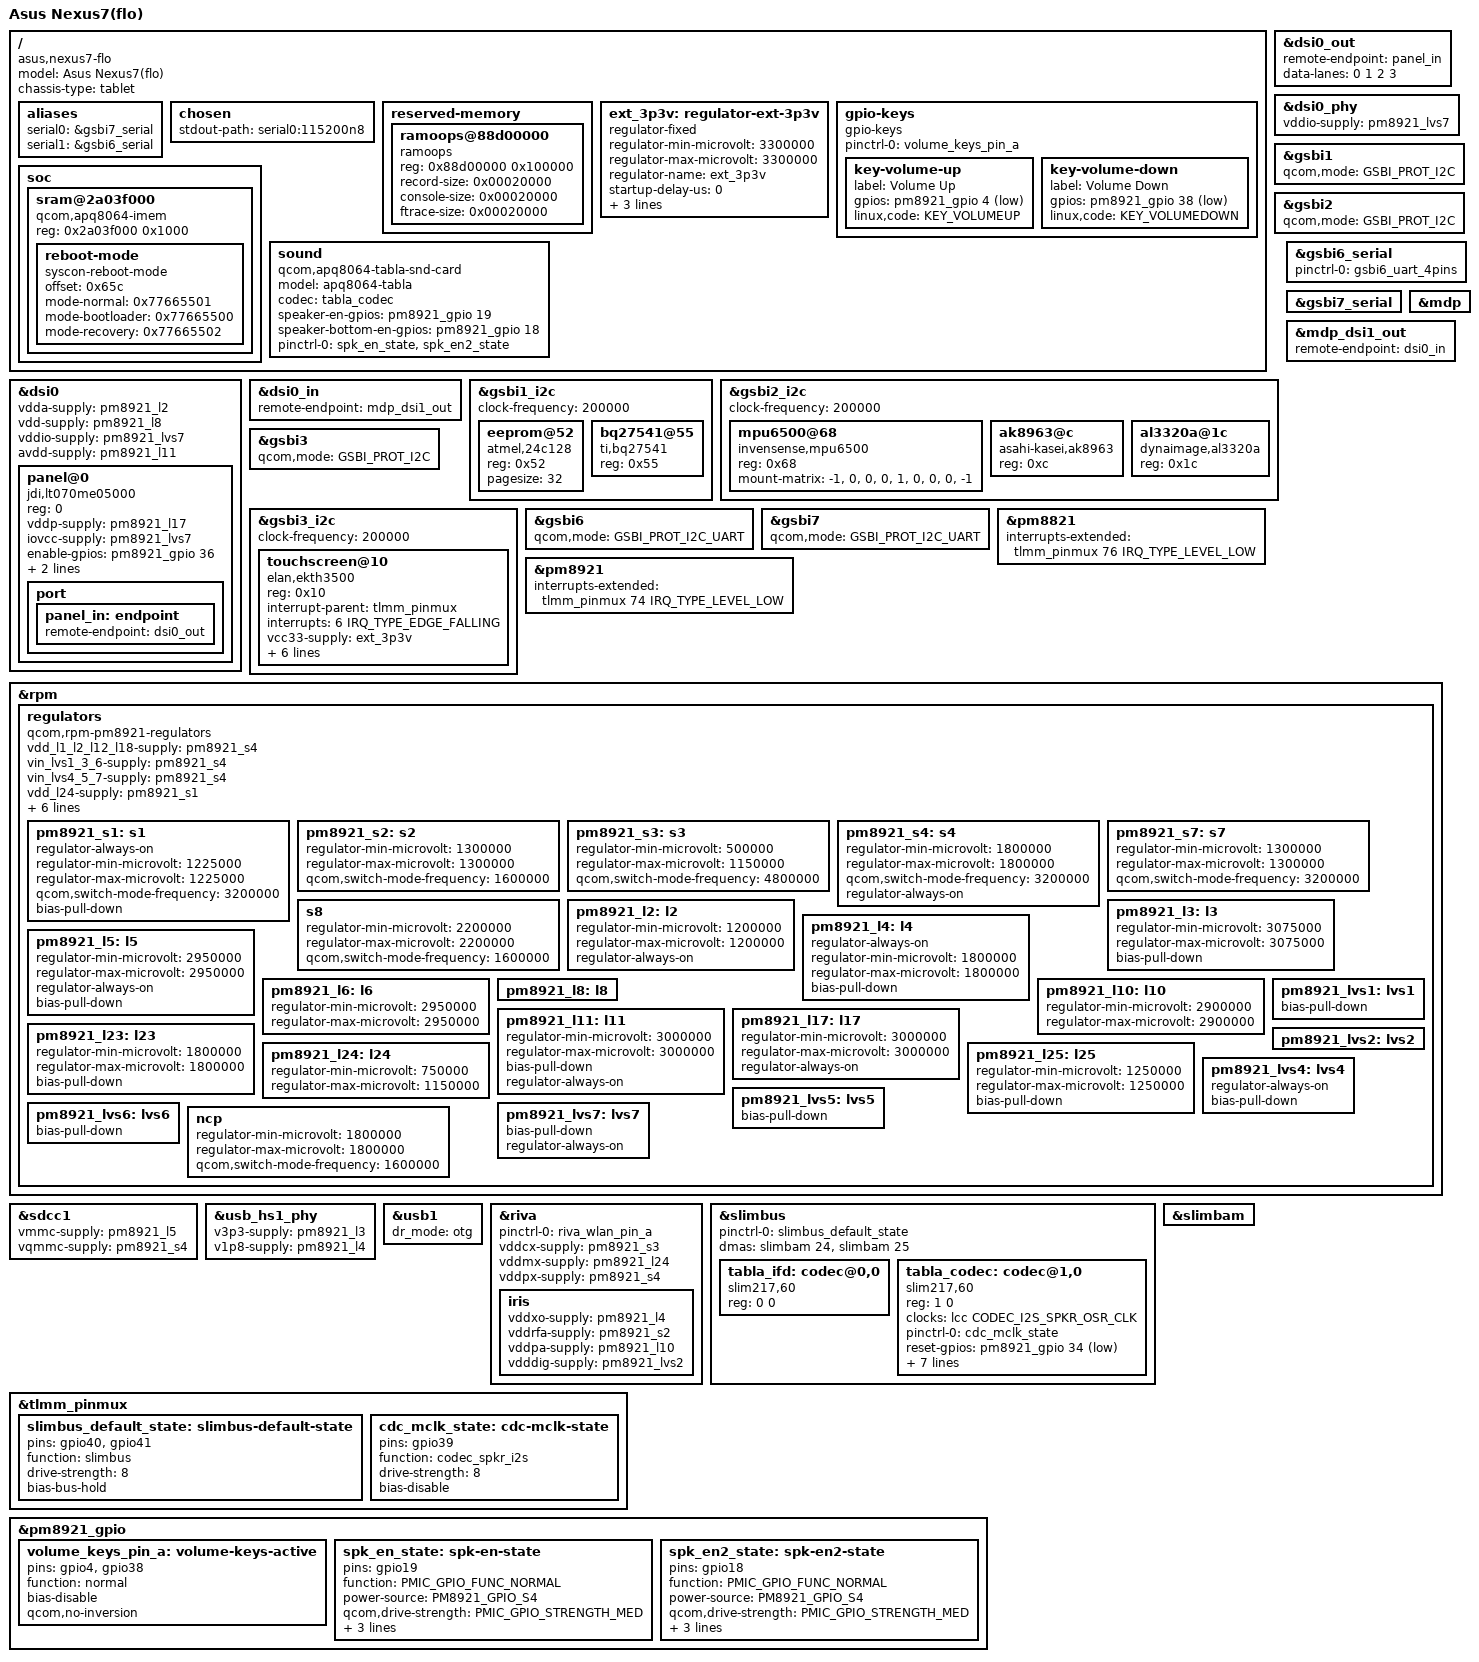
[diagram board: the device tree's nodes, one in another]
// SPDX-License-Identifier: GPL-2.0
#include <dt-bindings/gpio/gpio.h>
#include <dt-bindings/input/input.h>
#include <dt-bindings/pinctrl/qcom,pmic-gpio.h>
#include <dt-bindings/clock/qcom,lcc-msm8960.h>

#include "qcom-apq8064-v2.0.dtsi"
#include "pm8821.dtsi"
#include "pm8921.dtsi"

/ {
	model = "Asus Nexus7(flo)";
	compatible = "asus,nexus7-flo", "qcom,apq8064";
	chassis-type = "tablet";

	aliases {
		serial0 = &gsbi7_serial;
		serial1 = &gsbi6_serial;
	};

	chosen {
		stdout-path = "serial0:115200n8";
	};

	reserved-memory {
		#address-cells = <1>;
		#size-cells = <1>;
		ranges;

		ramoops@88d00000 {
			compatible = "ramoops";
			reg = <0x88d00000 0x100000>;
			record-size = <0x00020000>;
			console-size = <0x00020000>;
			ftrace-size = <0x00020000>;
		};
	};

	ext_3p3v: regulator-ext-3p3v {
		compatible = "regulator-fixed";
		regulator-min-microvolt = <3300000>;
		regulator-max-microvolt = <3300000>;
		regulator-name = "ext_3p3v";
		startup-delay-us = <0>;
		gpio = <&tlmm_pinmux 77 GPIO_ACTIVE_HIGH>;
		enable-active-high;
		regulator-boot-on;
	};

	gpio-keys {
		compatible = "gpio-keys";
		pinctrl-names = "default";
		pinctrl-0 = <&volume_keys_pin_a>;

		key-volume-up {
			label = "Volume Up";
			gpios = <&pm8921_gpio 4 GPIO_ACTIVE_LOW>;
			linux,code = <KEY_VOLUMEUP>;
		};
		key-volume-down {
			label = "Volume Down";
			gpios = <&pm8921_gpio 38 GPIO_ACTIVE_LOW>;
			linux,code = <KEY_VOLUMEDOWN>;
		};
	};

	soc {
		sram@2a03f000 {
			compatible = "qcom,apq8064-imem", "syscon", "simple-mfd";
			reg = <0x2a03f000 0x1000>;

			reboot-mode {
				compatible = "syscon-reboot-mode";
				offset = <0x65c>;

				mode-normal = <0x77665501>;
				mode-bootloader = <0x77665500>;
				mode-recovery = <0x77665502>;
			};
		};
	};

	sound {
		compatible = "qcom,apq8064-tabla-snd-card";
		model = "apq8064-tabla";
		codec = <&tabla_codec>;
		speaker-en-gpios = <&pm8921_gpio 19 GPIO_ACTIVE_HIGH>;
		speaker-bottom-en-gpios = <&pm8921_gpio 18 GPIO_ACTIVE_HIGH>;
		pinctrl-names = "default";
		pinctrl-0 = <&spk_en_state>, <&spk_en2_state>;
	};
};

&dsi0 {
	vdda-supply = <&pm8921_l2>;/*VDD_MIPI1 to 4*/
	vdd-supply = <&pm8921_l8>;
	vddio-supply = <&pm8921_lvs7>;
	avdd-supply = <&pm8921_l11>;
	status = "okay";

	panel@0 {
		reg = <0>;
		compatible = "jdi,lt070me05000";

		vddp-supply = <&pm8921_l17>;
		iovcc-supply = <&pm8921_lvs7>;

		enable-gpios = <&pm8921_gpio 36 GPIO_ACTIVE_HIGH>;
		reset-gpios = <&tlmm_pinmux 54 GPIO_ACTIVE_LOW>;
		dcdc-en-gpios = <&pm8921_gpio 23 GPIO_ACTIVE_HIGH>;

		port {
			panel_in: endpoint {
				remote-endpoint = <&dsi0_out>;
			};
		};
	};
};

&dsi0_in {
	remote-endpoint = <&mdp_dsi1_out>;
};

&dsi0_out {
	remote-endpoint = <&panel_in>;
	data-lanes = <0 1 2 3>;
};

&dsi0_phy {
	vddio-supply = <&pm8921_lvs7>;/*VDD_PLL2_1 to 7*/
	status = "okay";
};

&gsbi1 {
	qcom,mode = <GSBI_PROT_I2C>;
	status = "okay";
};

&gsbi1_i2c {
	status = "okay";
	clock-frequency = <200000>;

	eeprom@52 {
		compatible = "atmel,24c128";
		reg = <0x52>;
		pagesize = <32>;
	};

	bq27541@55 {
		compatible = "ti,bq27541";
		reg = <0x55>;
	};

};

/*
 * GSBI2 I2C bus: motion/sensor hub with MPU6500 (accel/gyro, 0x68),
 * AK8963 (magnetometer, 0x0c) and AL3320A (ALS, 0x1c). The stock kernel
 * drives these from the DSPS coprocessor; here the AP polls them over
 * I2C. pm8921_lvs4 (1.8V) is the bus pull-up rail and is kept on below.
 */
&gsbi2 {
	qcom,mode = <GSBI_PROT_I2C>;
	status = "okay";
};

&gsbi2_i2c {
	status = "okay";
	clock-frequency = <200000>;

	mpu6500@68 {
		compatible = "invensense,mpu6500";
		reg = <0x68>;

		/*
		 * The sensor is mounted rotated 180 degrees about the Y axis
		 * relative to the panel's natural landscape orientation. Without
		 * this, the natural (upright) landscape reads as InverseLandscape
		 * and the display renders upside-down. Flipping X (and Z) corrects
		 * the 180-degree landscape error while leaving Y (portrait) intact.
		 */
		mount-matrix = "-1", "0", "0",
						"0",  "1", "0",
						"0",  "0", "-1";
	};

	ak8963@c {
		compatible = "asahi-kasei,ak8963";
		reg = <0xc>;
	};

	al3320a@1c {
		compatible = "dynaimage,al3320a";
		reg = <0x1c>;
	};
};

&gsbi3 {
	qcom,mode = <GSBI_PROT_I2C>;
	status = "okay";
};

&gsbi3_i2c {
	clock-frequency = <200000>;
	status = "okay";

	touchscreen@10 {
		compatible = "elan,ekth3500";
		reg = <0x10>;

		interrupt-parent = <&tlmm_pinmux>;
		interrupts = <6 IRQ_TYPE_EDGE_FALLING>;

		vcc33-supply = <&ext_3p3v>;
		vccio-supply = <&pm8921_lvs7>;
		pinctrl-names = "default";
		pinctrl-0 = <&touch_pins>;

		touchscreen-size-x = <2240>;
		touchscreen-size-y = <1350>;
		touchscreen-swapped-x-y;
		touchscreen-inverted-x;
	};
};

&gsbi6 {
	qcom,mode = <GSBI_PROT_I2C_UART>;
	status = "okay";
};

&gsbi6_serial {
	pinctrl-names = "default";
	pinctrl-0 = <&gsbi6_uart_4pins>;
	status = "okay";
};

&gsbi7 {
	qcom,mode = <GSBI_PROT_I2C_UART>;
	status = "okay";
};

&gsbi7_serial {
	status = "okay";
};

&mdp {
	status = "okay";
};

&mdp_dsi1_out {
	remote-endpoint = <&dsi0_in>;
};

&pm8821 {
	interrupts-extended = <&tlmm_pinmux 76 IRQ_TYPE_LEVEL_LOW>;
};

&pm8921 {
	interrupts-extended = <&tlmm_pinmux 74 IRQ_TYPE_LEVEL_LOW>;
};

&rpm {
	regulators {
		compatible = "qcom,rpm-pm8921-regulators";

		vdd_l1_l2_l12_l18-supply = <&pm8921_s4>;
		vin_lvs1_3_6-supply = <&pm8921_s4>;
		vin_lvs4_5_7-supply = <&pm8921_s4>;

		vdd_l24-supply = <&pm8921_s1>;
		vdd_l25-supply = <&pm8921_s1>;
		vin_lvs2-supply = <&pm8921_s1>;

		vdd_l26-supply = <&pm8921_s7>;
		vdd_l27-supply = <&pm8921_s7>;
		vdd_l28-supply = <&pm8921_s7>;

		vdd_ncp-supply = <&pm8921_l6>;

		/* Buck SMPS */
		pm8921_s1: s1 {
			regulator-always-on;
			regulator-min-microvolt = <1225000>;
			regulator-max-microvolt = <1225000>;
			qcom,switch-mode-frequency = <3200000>;
			bias-pull-down;
		};

		/* wcnss_wlan.0-iris_vddrfa */
		pm8921_s2: s2 {
			regulator-min-microvolt = <1300000>;
			regulator-max-microvolt = <1300000>;
			qcom,switch-mode-frequency = <1600000>;
		};

		/* msm otg HSUSB_VDDCX */
		pm8921_s3: s3 {
			regulator-min-microvolt = <500000>;
			regulator-max-microvolt = <1150000>;
			qcom,switch-mode-frequency = <4800000>;
		};

		/*
		 * msm_sdcc.1-sdc-vdd_io
		 * tabla2x-slim-CDC_VDDA_RX
		 * tabla2x-slim-CDC_VDDA_TX
		 * tabla2x-slim-CDC_VDD_CP
		 * tabla2x-slim-VDDIO_CDC
		 */
		pm8921_s4: s4 {
			regulator-min-microvolt = <1800000>;
			regulator-max-microvolt = <1800000>;
			qcom,switch-mode-frequency = <3200000>;
			regulator-always-on;
		};

		pm8921_s7: s7 {
			regulator-min-microvolt = <1300000>;
			regulator-max-microvolt = <1300000>;
			qcom,switch-mode-frequency = <3200000>;
		};

		s8 {
			regulator-min-microvolt = <2200000>;
			regulator-max-microvolt = <2200000>;
			qcom,switch-mode-frequency = <1600000>;
		};

		/* mipi_dsi.1-dsi1_pll_vdda */
		pm8921_l2: l2 {
			regulator-min-microvolt = <1200000>;
			regulator-max-microvolt = <1200000>;
			regulator-always-on;
		};

		/* msm_otg-HSUSB_3p3 */
		pm8921_l3: l3 {
			regulator-min-microvolt = <3075000>;
			regulator-max-microvolt = <3075000>;
			bias-pull-down;
		};

		/* msm_otg-HSUSB_1p8 */
		pm8921_l4: l4 {
			regulator-always-on;
			regulator-min-microvolt = <1800000>;
			regulator-max-microvolt = <1800000>;
			bias-pull-down;
		};

		/* msm_sdcc.1-sdc_vdd */
		pm8921_l5: l5 {
			regulator-min-microvolt = <2950000>;
			regulator-max-microvolt = <2950000>;
			regulator-always-on;
			bias-pull-down;
		};

		pm8921_l6: l6 {
			regulator-min-microvolt = <2950000>;
			regulator-max-microvolt = <2950000>;
		};

		pm8921_l8: l8 {
		};

		/* wcnss_wlan.0-iris_vddpa */
		pm8921_l10: l10 {
			regulator-min-microvolt = <2900000>;
			regulator-max-microvolt = <2900000>;
		};

		/* mipi_dsi.1-dsi1_avdd */
		pm8921_l11: l11 {
			regulator-min-microvolt = <3000000>;
			regulator-max-microvolt = <3000000>;
			bias-pull-down;
			regulator-always-on;
		};

		/* pwm_power for backlight */
		pm8921_l17: l17 {
			regulator-min-microvolt = <3000000>;
			regulator-max-microvolt = <3000000>;
			regulator-always-on;
		};

		/* camera, qdsp6 */
		pm8921_l23: l23 {
			regulator-min-microvolt = <1800000>;
			regulator-max-microvolt = <1800000>;
			bias-pull-down;
		};

		/* wcnss_wlan.0-riva_vddmx */
		pm8921_l24: l24 {
			regulator-min-microvolt = <750000>;
			regulator-max-microvolt = <1150000>;
		};

		/*
		 * tabla2x-slim-CDC_VDDA_A_1P2V
		 * tabla2x-slim-VDDD_CDC_D
		 */
		pm8921_l25: l25 {
			regulator-min-microvolt = <1250000>;
			regulator-max-microvolt = <1250000>;
			bias-pull-down;
		};

		pm8921_lvs1: lvs1 {
			bias-pull-down;
		};

		/* wcnss_wlan.0-iris_vdddig */
		pm8921_lvs2: lvs2 {
		};

		/* I2C pull-up rail for the GSBI2 sensor bus; must stay on. */
		pm8921_lvs4: lvs4 {
			regulator-always-on;
			bias-pull-down;
		};

		pm8921_lvs5: lvs5 {
			bias-pull-down;
		};

		pm8921_lvs6: lvs6 {
			bias-pull-down;
		};
		/*
		 * mipi_dsi.1-dsi1_vddio
		 * pil_riva-pll_vdd
		 */
		pm8921_lvs7: lvs7 {
			bias-pull-down;
			regulator-always-on;
		};
		ncp {
			regulator-min-microvolt = <1800000>;
			regulator-max-microvolt = <1800000>;
			qcom,switch-mode-frequency = <1600000>;
		};
	};
};

/* eMMC */
&sdcc1 {
	vmmc-supply = <&pm8921_l5>;
	vqmmc-supply = <&pm8921_s4>;
	status = "okay";
};

&usb_hs1_phy {
	v3p3-supply = <&pm8921_l3>;
	v1p8-supply = <&pm8921_l4>;
};

/* OTG */
&usb1 {
	dr_mode = "otg";
	status = "okay";
};

&riva {
	status = "okay";
	pinctrl-names = "default";
	pinctrl-0 = <&riva_wlan_pin_a>;

	vddcx-supply = <&pm8921_s3>;
	vddmx-supply = <&pm8921_l24>;
	vddpx-supply = <&pm8921_s4>;

	iris {
		vddxo-supply = <&pm8921_l4>;
		vddrfa-supply = <&pm8921_s2>;
		vddpa-supply = <&pm8921_l10>;
		vdddig-supply = <&pm8921_lvs2>;
	};
};

&slimbus {
	pinctrl-names = "default";
	pinctrl-0 = <&slimbus_default_state>;
	status = "okay";

	/*
	 * A second TX channel for the second SLIM manager port (BAM pipe 25),
	 * used for the right audio channel in stereo playback.
	 */
	dmas = <&slimbam 24>, <&slimbam 25>;
	dma-names = "tx0", "tx1";

	tabla_ifd: codec@0,0 {
		compatible = "slim217,60";
		reg = <0 0>;
	};

	tabla_codec: codec@1,0 {
		compatible = "slim217,60";
		reg = <1 0>;

		clocks = <&lcc CODEC_I2S_SPKR_OSR_CLK>;
		clock-names = "mclk";
		pinctrl-names = "default";
		pinctrl-0 = <&cdc_mclk_state>;

		reset-gpios = <&pm8921_gpio 34 GPIO_ACTIVE_LOW>;
		slim-ifc-dev = <&tabla_ifd>;
		#sound-dai-cells = <0>;

		cdc-vdd-cp-supply = <&pm8921_s4>;
		cdc-vdda-rx-supply = <&pm8921_s4>;
		cdc-vdda-tx-supply = <&pm8921_s4>;
		vddio-cdc-supply = <&pm8921_s4>;
		vddd-cdc-d-supply = <&pm8921_l25>;
		cdc-vdda-a-1p2v-supply = <&pm8921_l25>;
	};
};

&slimbam {
	status = "okay";
};

&tlmm_pinmux {
	slimbus_default_state: slimbus-default-state {
		pins = "gpio40", "gpio41";
		function = "slimbus";
		drive-strength = <8>;
		bias-bus-hold;
	};

	cdc_mclk_state: cdc-mclk-state {
		pins = "gpio39";
		function = "codec_spkr_i2s";
		drive-strength = <8>;
		bias-disable;
	};

};

&pm8921_gpio {
	volume_keys_pin_a: volume-keys-active {
		pins = "gpio4", "gpio38";
		function = "normal";
		bias-disable;
		qcom,no-inversion;
	};

	spk_en_state: spk-en-state {
		pins = "gpio19";
		function = PMIC_GPIO_FUNC_NORMAL;
		power-source = <PM8921_GPIO_S4>;
		qcom,drive-strength = <PMIC_GPIO_STRENGTH_MED>;
		drive-push-pull;
		bias-disable;
		output-low;
	};

	spk_en2_state: spk-en2-state {
		pins = "gpio18";
		function = PMIC_GPIO_FUNC_NORMAL;
		power-source = <PM8921_GPIO_S4>;
		qcom,drive-strength = <PMIC_GPIO_STRENGTH_MED>;
		drive-push-pull;
		bias-disable;
		output-low;
	};
};
